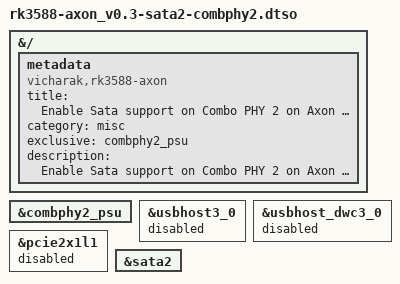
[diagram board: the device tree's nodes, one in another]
/dts-v1/;
/plugin/;

#include <dt-bindings/gpio/gpio.h>
#include <dt-bindings/pinctrl/rockchip.h>
#include <dt-bindings/interrupt-controller/irq.h>

&{/} {
	metadata {
		title ="Enable Sata support on Combo PHY 2 on Axon V0.3";
		compatible = "vicharak,rk3588-axon", "rockchip,rk3588";
		category = "misc";
		exclusive = "combphy2_psu";
		description = "Enable Sata support on Combo PHY 2 on Axon V0.3 accessible via external flex cable.\n\t - Provides support for Sata interface supporting maximum speed of 6.0 Gbps.\n\t - Designed for operating Sata-based devices such as SSDs, Optical Drives etc.\n\t - Caution: This will disable support for USB 3.0 and PCIe 2.0 Lane 1.";
	};
};

&combphy2_psu {
	status = "okay";
};

&usbhost3_0 {
	status = "disabled";
};      
        
&usbhost_dwc3_0 {
	status = "disabled";
};

&pcie2x1l1 {
	status = "disabled";
};

&sata2 {
        status = "okay";
};
